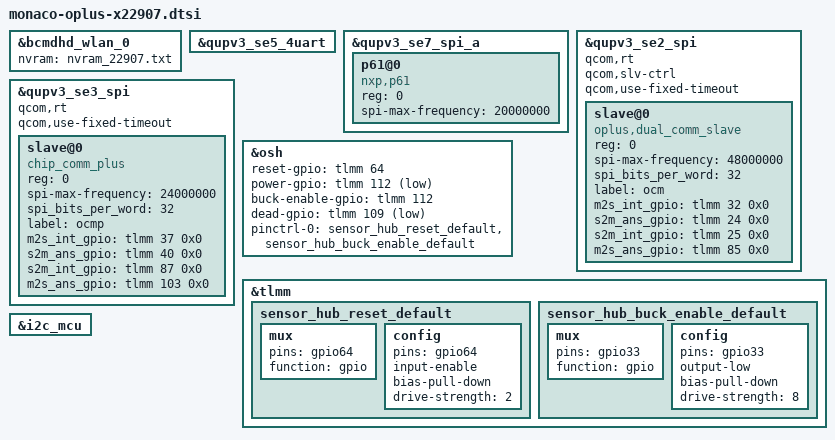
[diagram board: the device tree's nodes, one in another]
//From: qcom/monaco-standalone-idp-v1.dtsi

#include "monaco-oplus-common22x.dtsi"
#include "monaco-oplus-commonx907.dtsi"
#include "audio/monaco-oplus-audio-x22907.dtsi"
#include "haptic/aw86927.dtsi"
#include "battery/qbg-battery-base.dtsi"

&bcmdhd_wlan_0 {
	nvram = "nvram_22907.txt";
};

&qupv3_se5_4uart {
	status = "okay";
};

&qupv3_se7_spi_a {
	status = "ok";

	p61@0 {
		compatible = "nxp,p61";
		reg = <0>;
		spi-max-frequency = <20000000>;
	};
};

&qupv3_se2_spi {
	status = "okay";
	qcom,rt;
	qcom,slv-ctrl;
	//slv-cross-connected;
	//qcom,disable-autosuspend;
	qcom,use-fixed-timeout;

	slave@0 {
		compatible = "oplus,dual_comm_slave";
		reg = <0>;
		spi-max-frequency = <48000000>;
		spi_bits_per_word = <32>;
		label = "ocm";
		m2s_int_gpio = <&tlmm 32 0x0>;
		s2m_ans_gpio = <&tlmm 24 0x0>;
		s2m_int_gpio = <&tlmm 25 0x0>;
		m2s_ans_gpio = <&tlmm 85 0x0>;
	};
};

&qupv3_se3_spi { /*dual communication*/
	status = "ok";
	qcom,rt;
	//qcom,slv-ctrl;
	//slv-cross-connected;
	//qcom,disable-autosuspend;
	qcom,use-fixed-timeout;

	slave@0 {
		status = "ok";
		compatible = "chip_comm_plus";
		reg = <0>;
		spi-max-frequency = <24000000>;
		spi_bits_per_word = <32>;
		label = "ocmp";
		m2s_int_gpio = <&tlmm 37 0x0>;
		s2m_ans_gpio = <&tlmm 40 0x0>;
		s2m_int_gpio = <&tlmm 87 0x0>;
		m2s_ans_gpio = <&tlmm 103 0x0>;
	};
};

&osh {
	reset-gpio = <&tlmm 64 GPIO_ACTIVE_HIGH>;
	power-gpio = <&tlmm 112 GPIO_ACTIVE_LOW>;
	buck-enable-gpio = <&tlmm 112 GPIO_ACTIVE_HIGH>;
	//ap-suspend-gpio = <&tlmm 42 0>;
	dead-gpio = <&tlmm 109 GPIO_ACTIVE_LOW>;

	pinctrl-names = "default";
	pinctrl-0 = <&sensor_hub_reset_default &sensor_hub_buck_enable_default>;
};


&tlmm {
	sensor_hub_reset_default: sensor_hub_reset_default {
		mux {
			pins = "gpio64";
			function = "gpio";
		};
		config {
			pins = "gpio64";
			input-enable;
			bias-pull-down;
			drive-strength = <2>; /* 2 MA */
		};
	};

	sensor_hub_buck_enable_default: sensor_hub_buck_enable_default {
		mux {
			pins = "gpio33";
			function = "gpio";
		};
		config {
			pins = "gpio33";
			output-low;
			bias-pull-down;
			drive-strength = <8>; /* 8 MA */
		};
	};
};
&i2c_mcu {
    status = "ok";
};
